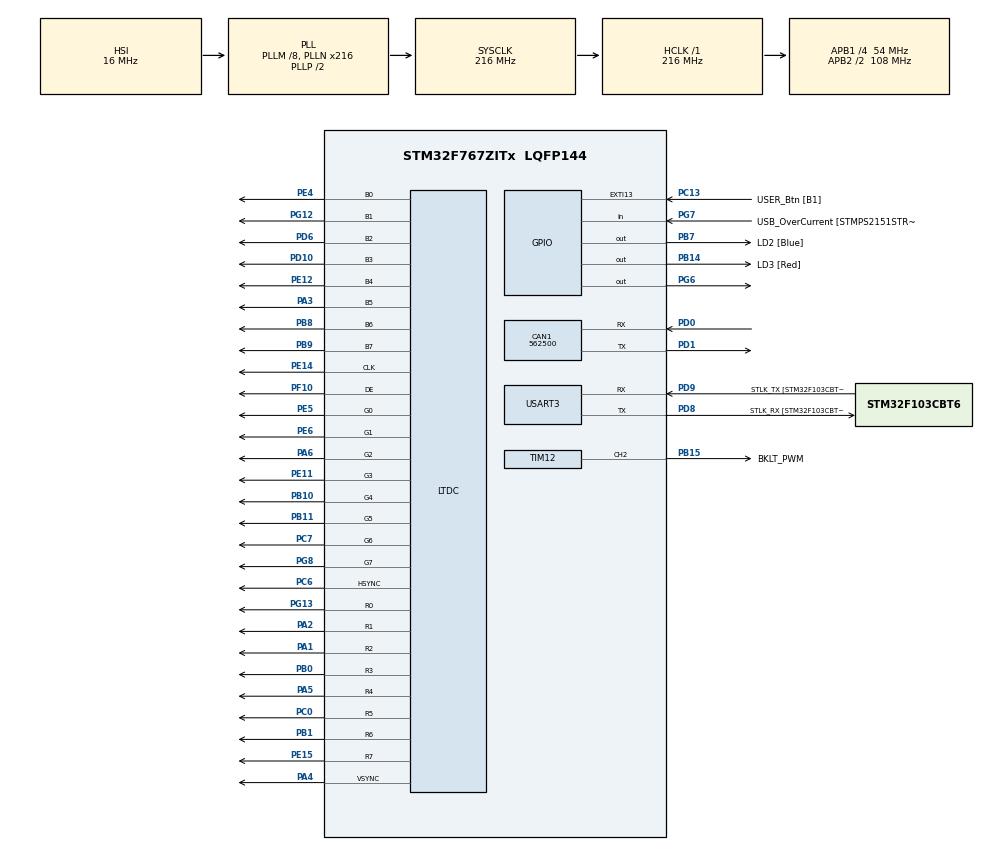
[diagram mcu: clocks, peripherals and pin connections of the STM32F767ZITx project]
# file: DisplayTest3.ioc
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ADC1.Channel-0\#ChannelRegularConversion=ADC_CHANNEL_TEMPSENSOR
ADC1.NbrOfConversionFlag=1
ADC1.Rank-0\#ChannelRegularConversion=1
ADC1.SamplingTime-0\#ChannelRegularConversion=ADC_SAMPLETIME_3CYCLES
ADC1.master=1
CAN1.BS1=CAN_BS1_2TQ
CAN1.BS2=CAN_BS2_3TQ
CAN1.CalculateBaudRate=562500
CAN1.CalculateTimeBit=1777
CAN1.CalculateTimeQuantum=296.2962962962963
CAN1.SJW=CAN_SJW_2TQ
CORTEX_M7.ART_ACCELERATOR_ENABLE=1
CORTEX_M7.CPU_DCache=Disabled
CORTEX_M7.CPU_ICache=Enabled
CORTEX_M7.PREFETCH_ENABLE=1
DMA2D.ColorMode=DMA2D_OUTPUT_RGB565
LTDC.ActiveW=480
LTDC.Alpha0_L0=128
LTDC.Alpha_L0=255
LTDC.BlendingFactor1_L0=LTDC_BLENDING_FACTOR1_PAxCA
LTDC.BlendingFactor2_L0=LTDC_BLENDING_FACTOR2_PAxCA
LTDC.Blue_L0=255
LTDC.Green=0
LTDC.Green_L0=0
LTDC.HBP=40
LTDC.HFP=5
LTDC.ImageHeight_L0=RENDER_V
LTDC.ImageWidth_L0=RENDER_H
LTDC.Layers=0
LTDC.PixelFormat_L0=LTDC_PIXEL_FORMAT_RGB565
LTDC.Red=0
LTDC.Red_L0=0
LTDC.VBP=8
LTDC.VFP=8
LTDC.WindowX1_L0=RENDER_H
LTDC.WindowY1_L0=RENDER_V
Mcu.Family=STM32F7
Mcu.Name=STM32F767ZITx
Mcu.Package=LQFP144
Mcu.UserConstants=RENDER_H,480;RENDER_V,272
NVIC.DMA2D_IRQn=true\:0\:0\:false\:false\:true\:true\:true\:true
NVIC.PriorityGroup=NVIC_PRIORITYGROUP_4
PA1.Mode=RGB888
PA1.Signal=LTDC_R2
PA10.GPIO_Label=USB_ID
PA10.Signal=USB_OTG_FS_ID
PA11.GPIO_Label=USB_DM
PA11.Signal=USB_OTG_FS_DM
PA12.GPIO_Label=USB_DP
PA12.Signal=USB_OTG_FS_DP
PA13.GPIO_Label=TMS
PA13.Mode=Serial_Wire
PA13.Signal=SYS_JTMS-SWDIO
PA14.GPIO_Label=TCK
PA14.Mode=Serial_Wire
PA14.Signal=SYS_JTCK-SWCLK
PA2.Mode=RGB888
PA2.Signal=LTDC_R1
PA3.Mode=RGB888
PA3.Signal=LTDC_B5
PA4.Mode=RGB888
PA4.Signal=LTDC_VSYNC
PA5.Mode=RGB888
PA5.Signal=LTDC_R4
PA6.Mode=RGB888
PA6.Signal=LTDC_G2
PA7.GPIO_Label=RMII_CRS_DV [LAN8742A-CZ-TR_CRS_DV]
PA7.Signal=ETH_CRS_DV
PA8.GPIO_Label=USB_SOF [TP1]
PA8.Signal=USB_OTG_FS_SOF
PA9.GPIO_Label=USB_VBUS
PA9.Signal=USB_OTG_FS_VBUS
PB0.Mode=RGB888
PB0.Signal=LTDC_R3
PB1.Mode=RGB888
PB1.Signal=LTDC_R6
PB10.Mode=RGB888
PB10.Signal=LTDC_G4
PB11.Mode=RGB888
PB11.Signal=LTDC_G5
PB14.GPIO_Label=LD3 [Red]
PB14.Signal=GPIO_Output
PB15.GPIO_Label=BKLT_PWM
PB15.Signal=S_TIM12_CH2
PB3.GPIO_Label=SWO
PB3.Signal=SYS_JTDO-SWO
PB7.GPIO_Label=LD2 [Blue]
PB7.Signal=GPIO_Output
PB8.Mode=RGB888
PB8.Signal=LTDC_B6
PB9.Mode=RGB888
PB9.Signal=LTDC_B7
PC0.Mode=RGB888
PC0.Signal=LTDC_R5
PC1.GPIO_Label=RMII_MDC [LAN8742A-CZ-TR_MDC]
PC1.Signal=ETH_MDC
PC13.GPIO_Label=USER_Btn [B1]
PC13.Signal=GPXTI13
PC14/OSC32_IN.Signal=RCC_OSC32_IN
PC15/OSC32_OUT.Signal=RCC_OSC32_OUT
PC4.GPIO_Label=RMII_RXD0 [LAN8742A-CZ-TR_RXD0]
PC4.Signal=ETH_RXD0
PC5.GPIO_Label=RMII_RXD1 [LAN8742A-CZ-TR_RXD1]
PC5.Signal=ETH_RXD1
PC6.Mode=RGB888
PC6.Signal=LTDC_HSYNC
PC7.Mode=RGB888
PC7.Signal=LTDC_G6
PD0.Mode=CAN_Activate
PD0.Signal=CAN1_RX
PD1.Mode=CAN_Activate
PD1.Signal=CAN1_TX
PD10.Mode=RGB888
PD10.Signal=LTDC_B3
PD6.Mode=RGB888
PD6.Signal=LTDC_B2
PD8.GPIO_Label=STLK_RX [STM32F103CBT6_PA3]
PD8.Mode=Asynchronous
PD8.Signal=USART3_TX
PD9.GPIO_Label=STLK_TX [STM32F103CBT6_PA2]
PD9.Mode=Asynchronous
PD9.Signal=USART3_RX
PE11.Mode=RGB888
PE11.Signal=LTDC_G3
PE12.Mode=RGB888
PE12.Signal=LTDC_B4
PE14.Mode=RGB888
PE14.Signal=LTDC_CLK
PE15.Mode=RGB888
PE15.Signal=LTDC_R7
PE4.Mode=RGB888
PE4.Signal=LTDC_B0
PE5.Mode=RGB888
PE5.Signal=LTDC_G0
PE6.Mode=RGB888
PE6.Signal=LTDC_G1
PF10.Mode=RGB888
PF10.Signal=LTDC_DE
PG12.Mode=RGB888
PG12.Signal=LTDC_B1
PG13.Mode=RGB888
PG13.Signal=LTDC_R0
PG6.Signal=GPIO_Output
PG7.GPIO_Label=USB_OverCurrent [STMPS2151STR_FAULT]
PG7.Signal=GPIO_Input
PG8.Mode=RGB888
PG8.Signal=LTDC_G7
PH0/OSC_IN.GPIO_Label=MCO [STM32F103CBT6_PA8]
PH0/OSC_IN.Signal=RCC_OSC_IN
PH1/OSC_OUT.Signal=RCC_OSC_OUT
ProjectManager.HeapSize=0x200
ProjectManager.StackSize=0x400
ProjectManager.TargetToolchain=STM32CubeIDE
RCC.48MHZClocksFreq_Value=24000000
RCC.AHBFreq_Value=216000000
RCC.APB1CLKDivider=RCC_HCLK_DIV4
RCC.APB1Freq_Value=54000000
RCC.APB1TimFreq_Value=108000000
RCC.APB2CLKDivider=RCC_HCLK_DIV2
RCC.APB2Freq_Value=108000000
RCC.APB2TimFreq_Value=216000000
RCC.CortexFreq_Value=216000000
RCC.HCLKFreq_Value=216000000
RCC.HSE_VALUE=8000000
RCC.HSI_VALUE=16000000
RCC.LSE_VALUE=32768
RCC.PLLM=8
RCC.PLLMUL=RCC_PLL_MUL9
RCC.PLLN=216
RCC.PLLQ=9
RCC.PLLSAIN=96
RCC.PLLSAIRDiv=RCC_PLLSAIDIVR_8
RCC.PRESCALERUSB=RCC_USBCLKSOURCE_PLL_DIV1_5
RCC.SYSCLKFreq_VALUE=216000000
RCC.SYSCLKSource=RCC_SYSCLKSOURCE_PLLCLK
RCC.SYSCLKSourceVirtual=RCC_SYSCLKSOURCE_PLLCLK
RCC.USBFreq_Value=48000000
RCC.VCOOutputFreq_Value=432000000
SH.S_TIM12_CH2.0=TIM12_CH2,PWM Generation2 CH2
TIM12.Channel-PWM\ Generation2\ CH2=TIM_CHANNEL_2
USART3.VirtualMode-Asynchronous=VM_ASYNC
VP_ADC1_TempSens_Input.Mode=IN-TempSens
VP_ADC1_Vref_Input.Mode=IN-Vrefint
VP_DMA2D_VS_DMA2D.Mode=DMA2D_Activate
VP_TIM12_VS_ClockSourceINT.Mode=Internal
board=NUCLEO-F767ZI

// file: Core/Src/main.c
/* USER CODE BEGIN Header */
/**
  ******************************************************************************
  * @file           : main.c
  * @brief          : Main program body
  ******************************************************************************
  * @attention
  *
  * Copyright (c) 2024 STMicroelectronics.
  * All rights reserved.
  *
  * This software is licensed under terms that can be found in the LICENSE file
  * in the root directory of this software component.
  * If no LICENSE file comes with this software, it is provided AS-IS.
  *
  ******************************************************************************
  */
/* USER CODE END Header */
#include "main.h"

/* USER CODE BEGIN Includes */

#include "lvgl.h"
//#include "demos/stress/lv_demo_stress.h"
#include "ui.h"

/* USER CODE END Includes */

ADC_HandleTypeDef hadc1;

CAN_HandleTypeDef hcan1;

DMA2D_HandleTypeDef hdma2d;

LTDC_HandleTypeDef hltdc;

TIM_HandleTypeDef htim12;

UART_HandleTypeDef huart3;

/* USER CODE BEGIN PV */

uint32_t adc_data;
int temp;

/* USER CODE END PV */

void SystemClock_Config(void);
static void MX_GPIO_Init(void);
static void MX_USART3_UART_Init(void);
static void MX_CAN1_Init(void);
static void MX_LTDC_Init(void);
static void MX_DMA2D_Init(void);
static void MX_TIM12_Init(void);
static void MX_ADC1_Init(void);

int main(void)
{

  /* Enable the CPU Cache */

  /* Enable I-Cache---------------------------------------------------------*/
  SCB_EnableICache();

  /* MCU Configuration--------------------------------------------------------*/

  /* Reset of all peripherals, Initializes the Flash interface and the Systick. */
  HAL_Init();

  /* Configure the system clock */
  SystemClock_Config();

  /* Initialize all configured peripherals */
  MX_GPIO_Init();
  MX_USART3_UART_Init();
  MX_CAN1_Init();
  MX_LTDC_Init();
  MX_DMA2D_Init();
  MX_TIM12_Init();
  MX_ADC1_Init();
  /* USER CODE BEGIN 2 */

  // prepare temp sensor - define variable to be updated in main, start and calibrate adc with vrefint
//  HAL_ADC_Start(&hadc1);
//  HAL_ADCEx_Calibration_Start(&hadc1);

  // setup lvgl
  lv_init();
  lv_port_disp_init(&hltdc);
//  lv_demo_benchmark();
  ui_init();
  // show screen 2
  _ui_screen_change(&ui_Screen_Dark, LV_SCR_LOAD_ANIM_FADE_ON, 500, 0, ui_Screen_Dark_screen_init);
  _ui_screen_change(&ui_Screen_Loading, LV_SCR_LOAD_ANIM_FADE_ON, 500, 1000, ui_Screen_Loading_screen_init);
  _ui_screen_change(&ui_Screen_Main, LV_SCR_LOAD_ANIM_FADE_ON, 100, 5000, ui_Screen_Main_screen_init);

  /* USER CODE END 2 */

  /* Infinite loop */
  while (1)
  {

    /* USER CODE BEGIN 3 */
	// get temp sensor data
//	  HAL_ADC_PollForConversion(&hadc1, 100);
//	  adc_data = HAL_ADC_GetValue(&hadc1);
//	  temp = ((adc_data - 760) * 100) / 16;

	lv_task_handler();  // to be added
	HAL_Delay(5);  // to be added
  }
  /* USER CODE END 3 */
}

void SystemClock_Config(void)
{
  RCC_OscInitTypeDef RCC_OscInitStruct = {0};
  RCC_ClkInitTypeDef RCC_ClkInitStruct = {0};

  /** Configure the main internal regulator output voltage
  */
  __HAL_RCC_PWR_CLK_ENABLE();
  __HAL_PWR_VOLTAGESCALING_CONFIG(PWR_REGULATOR_VOLTAGE_SCALE1);

  /** Initializes the RCC Oscillators according to the specified parameters
  * in the RCC_OscInitTypeDef structure.
  */
  RCC_OscInitStruct.OscillatorType = RCC_OSCILLATORTYPE_HSI;
  RCC_OscInitStruct.HSIState = RCC_HSI_ON;
  RCC_OscInitStruct.HSICalibrationValue = RCC_HSICALIBRATION_DEFAULT;
  RCC_OscInitStruct.PLL.PLLState = RCC_PLL_ON;
  RCC_OscInitStruct.PLL.PLLSource = RCC_PLLSOURCE_HSI;
  RCC_OscInitStruct.PLL.PLLM = 8;
  RCC_OscInitStruct.PLL.PLLN = 216;
  RCC_OscInitStruct.PLL.PLLP = RCC_PLLP_DIV2;
  RCC_OscInitStruct.PLL.PLLQ = 9;
  RCC_OscInitStruct.PLL.PLLR = 2;
  if (HAL_RCC_OscConfig(&RCC_OscInitStruct) != HAL_OK)
  {
    Error_Handler();
  }

  /** Activate the Over-Drive mode
  */
  if (HAL_PWREx_EnableOverDrive() != HAL_OK)
  {
    Error_Handler();
  }

  /** Initializes the CPU, AHB and APB buses clocks
  */
  RCC_ClkInitStruct.ClockType = RCC_CLOCKTYPE_HCLK|RCC_CLOCKTYPE_SYSCLK
                              |RCC_CLOCKTYPE_PCLK1|RCC_CLOCKTYPE_PCLK2;
  RCC_ClkInitStruct.SYSCLKSource = RCC_SYSCLKSOURCE_PLLCLK;
  RCC_ClkInitStruct.AHBCLKDivider = RCC_SYSCLK_DIV1;
  RCC_ClkInitStruct.APB1CLKDivider = RCC_HCLK_DIV4;
  RCC_ClkInitStruct.APB2CLKDivider = RCC_HCLK_DIV2;

  if (HAL_RCC_ClockConfig(&RCC_ClkInitStruct, FLASH_LATENCY_7) != HAL_OK)
  {
    Error_Handler();
  }
}

static void MX_ADC1_Init(void)
{

  ADC_ChannelConfTypeDef sConfig = {0};

  /** Configure the global features of the ADC (Clock, Resolution, Data Alignment and number of conversion)
  */
  hadc1.Instance = ADC1;
  hadc1.Init.ClockPrescaler = ADC_CLOCK_SYNC_PCLK_DIV4;
  hadc1.Init.Resolution = ADC_RESOLUTION_12B;
  hadc1.Init.ScanConvMode = ADC_SCAN_DISABLE;
  hadc1.Init.ContinuousConvMode = DISABLE;
  hadc1.Init.DiscontinuousConvMode = DISABLE;
  hadc1.Init.ExternalTrigConvEdge = ADC_EXTERNALTRIGCONVEDGE_NONE;
  hadc1.Init.ExternalTrigConv = ADC_SOFTWARE_START;
  hadc1.Init.DataAlign = ADC_DATAALIGN_RIGHT;
  hadc1.Init.NbrOfConversion = 1;
  hadc1.Init.DMAContinuousRequests = DISABLE;
  hadc1.Init.EOCSelection = ADC_EOC_SINGLE_CONV;
  if (HAL_ADC_Init(&hadc1) != HAL_OK)
  {
    Error_Handler();
  }

  /** Configure for the selected ADC regular channel its corresponding rank in the sequencer and its sample time.
  */
  sConfig.Channel = ADC_CHANNEL_TEMPSENSOR;
  sConfig.Rank = ADC_REGULAR_RANK_1;
  sConfig.SamplingTime = ADC_SAMPLETIME_3CYCLES;
  if (HAL_ADC_ConfigChannel(&hadc1, &sConfig) != HAL_OK)
  {
    Error_Handler();
  }

}

static void MX_CAN1_Init(void)
{

  hcan1.Instance = CAN1;
  hcan1.Init.Prescaler = 16;
  hcan1.Init.Mode = CAN_MODE_NORMAL;
  hcan1.Init.SyncJumpWidth = CAN_SJW_2TQ;
  hcan1.Init.TimeSeg1 = CAN_BS1_2TQ;
  hcan1.Init.TimeSeg2 = CAN_BS2_3TQ;
  hcan1.Init.TimeTriggeredMode = DISABLE;
  hcan1.Init.AutoBusOff = DISABLE;
  hcan1.Init.AutoWakeUp = DISABLE;
  hcan1.Init.AutoRetransmission = DISABLE;
  hcan1.Init.ReceiveFifoLocked = DISABLE;
  hcan1.Init.TransmitFifoPriority = DISABLE;
  if (HAL_CAN_Init(&hcan1) != HAL_OK)
  {
    Error_Handler();
  }

}

static void MX_DMA2D_Init(void)
{

  hdma2d.Instance = DMA2D;
  hdma2d.Init.Mode = DMA2D_M2M;
  hdma2d.Init.ColorMode = DMA2D_OUTPUT_RGB565;
  hdma2d.Init.OutputOffset = 0;
  hdma2d.LayerCfg[1].InputOffset = 0;
  hdma2d.LayerCfg[1].InputColorMode = DMA2D_INPUT_RGB565;
  hdma2d.LayerCfg[1].AlphaMode = DMA2D_NO_MODIF_ALPHA;
  hdma2d.LayerCfg[1].InputAlpha = 0;
  hdma2d.LayerCfg[1].AlphaInverted = DMA2D_REGULAR_ALPHA;
  hdma2d.LayerCfg[1].RedBlueSwap = DMA2D_RB_REGULAR;
  if (HAL_DMA2D_Init(&hdma2d) != HAL_OK)
  {
    Error_Handler();
  }
  if (HAL_DMA2D_ConfigLayer(&hdma2d, 1) != HAL_OK)
  {
    Error_Handler();
  }

}

static void MX_LTDC_Init(void)
{

  LTDC_LayerCfgTypeDef pLayerCfg = {0};

  hltdc.Instance = LTDC;
  hltdc.Init.HSPolarity = LTDC_HSPOLARITY_AL;
  hltdc.Init.VSPolarity = LTDC_VSPOLARITY_AL;
  hltdc.Init.DEPolarity = LTDC_DEPOLARITY_AL;
  hltdc.Init.PCPolarity = LTDC_PCPOLARITY_IPC;
  hltdc.Init.HorizontalSync = 7;
  hltdc.Init.VerticalSync = 3;
  hltdc.Init.AccumulatedHBP = 47;
  hltdc.Init.AccumulatedVBP = 11;
  hltdc.Init.AccumulatedActiveW = 527;
  hltdc.Init.AccumulatedActiveH = 491;
  hltdc.Init.TotalWidth = 532;
  hltdc.Init.TotalHeigh = 499;
  hltdc.Init.Backcolor.Blue = 0;
  hltdc.Init.Backcolor.Green = 0;
  hltdc.Init.Backcolor.Red = 0;
  if (HAL_LTDC_Init(&hltdc) != HAL_OK)
  {
    Error_Handler();
  }
  pLayerCfg.WindowX0 = 0;
  pLayerCfg.WindowX1 = RENDER_H;
  pLayerCfg.WindowY0 = 0;
  pLayerCfg.WindowY1 = RENDER_V;
  pLayerCfg.PixelFormat = LTDC_PIXEL_FORMAT_RGB565;
  pLayerCfg.Alpha = 255;
  pLayerCfg.Alpha0 = 128;
  pLayerCfg.BlendingFactor1 = LTDC_BLENDING_FACTOR1_PAxCA;
  pLayerCfg.BlendingFactor2 = LTDC_BLENDING_FACTOR2_PAxCA;
  pLayerCfg.FBStartAdress = 0;
  pLayerCfg.ImageWidth = RENDER_H;
  pLayerCfg.ImageHeight = RENDER_V;
  pLayerCfg.Backcolor.Blue = 255;
  pLayerCfg.Backcolor.Green = 0;
  pLayerCfg.Backcolor.Red = 0;
  if (HAL_LTDC_ConfigLayer(&hltdc, &pLayerCfg, 0) != HAL_OK)
  {
    Error_Handler();
  }

}

static void MX_TIM12_Init(void)
{

  TIM_ClockConfigTypeDef sClockSourceConfig = {0};
  TIM_OC_InitTypeDef sConfigOC = {0};

  htim12.Instance = TIM12;
  htim12.Init.Prescaler = 0;
  htim12.Init.CounterMode = TIM_COUNTERMODE_UP;
  htim12.Init.Period = 65535;
  htim12.Init.ClockDivision = TIM_CLOCKDIVISION_DIV1;
  htim12.Init.AutoReloadPreload = TIM_AUTORELOAD_PRELOAD_DISABLE;
  if (HAL_TIM_Base_Init(&htim12) != HAL_OK)
  {
    Error_Handler();
  }
  sClockSourceConfig.ClockSource = TIM_CLOCKSOURCE_INTERNAL;
  if (HAL_TIM_ConfigClockSource(&htim12, &sClockSourceConfig) != HAL_OK)
  {
    Error_Handler();
  }
  if (HAL_TIM_PWM_Init(&htim12) != HAL_OK)
  {
    Error_Handler();
  }
  sConfigOC.OCMode = TIM_OCMODE_PWM1;
  sConfigOC.Pulse = 0;
  sConfigOC.OCPolarity = TIM_OCPOLARITY_HIGH;
  sConfigOC.OCFastMode = TIM_OCFAST_DISABLE;
  if (HAL_TIM_PWM_ConfigChannel(&htim12, &sConfigOC, TIM_CHANNEL_2) != HAL_OK)
  {
    Error_Handler();
  }
  HAL_TIM_MspPostInit(&htim12);

}

static void MX_USART3_UART_Init(void)
{

  huart3.Instance = USART3;
  huart3.Init.BaudRate = 115200;
  huart3.Init.WordLength = UART_WORDLENGTH_8B;
  huart3.Init.StopBits = UART_STOPBITS_1;
  huart3.Init.Parity = UART_PARITY_NONE;
  huart3.Init.Mode = UART_MODE_TX_RX;
  huart3.Init.HwFlowCtl = UART_HWCONTROL_NONE;
  huart3.Init.OverSampling = UART_OVERSAMPLING_16;
  huart3.Init.OneBitSampling = UART_ONE_BIT_SAMPLE_DISABLE;
  huart3.AdvancedInit.AdvFeatureInit = UART_ADVFEATURE_NO_INIT;
  if (HAL_UART_Init(&huart3) != HAL_OK)
  {
    Error_Handler();
  }

}

static void MX_GPIO_Init(void)
{
  GPIO_InitTypeDef GPIO_InitStruct = {0};

  /* GPIO Ports Clock Enable */
  __HAL_RCC_GPIOE_CLK_ENABLE();
  __HAL_RCC_GPIOC_CLK_ENABLE();
  __HAL_RCC_GPIOF_CLK_ENABLE();
  __HAL_RCC_GPIOH_CLK_ENABLE();
  __HAL_RCC_GPIOA_CLK_ENABLE();
  __HAL_RCC_GPIOB_CLK_ENABLE();
  __HAL_RCC_GPIOD_CLK_ENABLE();
  __HAL_RCC_GPIOG_CLK_ENABLE();

  /*Configure GPIO pin Output Level */
  HAL_GPIO_WritePin(GPIOB, LD3_Pin|LD2_Pin, GPIO_PIN_RESET);

  /*Configure GPIO pin Output Level */
  HAL_GPIO_WritePin(GPIOG, GPIO_PIN_6, GPIO_PIN_RESET);

  /*Configure GPIO pin : USER_Btn_Pin */
  GPIO_InitStruct.Pin = USER_Btn_Pin;
  GPIO_InitStruct.Mode = GPIO_MODE_IT_RISING;
  GPIO_InitStruct.Pull = GPIO_NOPULL;
  HAL_GPIO_Init(USER_Btn_GPIO_Port, &GPIO_InitStruct);

  /*Configure GPIO pins : RMII_MDC_Pin RMII_RXD0_Pin RMII_RXD1_Pin */
  GPIO_InitStruct.Pin = RMII_MDC_Pin|RMII_RXD0_Pin|RMII_RXD1_Pin;
  GPIO_InitStruct.Mode = GPIO_MODE_AF_PP;
  GPIO_InitStruct.Pull = GPIO_NOPULL;
  GPIO_InitStruct.Speed = GPIO_SPEED_FREQ_VERY_HIGH;
  GPIO_InitStruct.Alternate = GPIO_AF11_ETH;
  HAL_GPIO_Init(GPIOC, &GPIO_InitStruct);

  /*Configure GPIO pin : RMII_CRS_DV_Pin */
  GPIO_InitStruct.Pin = RMII_CRS_DV_Pin;
  GPIO_InitStruct.Mode = GPIO_MODE_AF_PP;
  GPIO_InitStruct.Pull = GPIO_NOPULL;
  GPIO_InitStruct.Speed = GPIO_SPEED_FREQ_VERY_HIGH;
  GPIO_InitStruct.Alternate = GPIO_AF11_ETH;
  HAL_GPIO_Init(RMII_CRS_DV_GPIO_Port, &GPIO_InitStruct);

  /*Configure GPIO pins : LD3_Pin LD2_Pin */
  GPIO_InitStruct.Pin = LD3_Pin|LD2_Pin;
  GPIO_InitStruct.Mode = GPIO_MODE_OUTPUT_PP;
  GPIO_InitStruct.Pull = GPIO_NOPULL;
  GPIO_InitStruct.Speed = GPIO_SPEED_FREQ_LOW;
  HAL_GPIO_Init(GPIOB, &GPIO_InitStruct);

  /*Configure GPIO pin : PG6 */
  GPIO_InitStruct.Pin = GPIO_PIN_6;
  GPIO_InitStruct.Mode = GPIO_MODE_OUTPUT_PP;
  GPIO_InitStruct.Pull = GPIO_NOPULL;
  GPIO_InitStruct.Speed = GPIO_SPEED_FREQ_LOW;
  HAL_GPIO_Init(GPIOG, &GPIO_InitStruct);

  /*Configure GPIO pin : USB_OverCurrent_Pin */
  GPIO_InitStruct.Pin = USB_OverCurrent_Pin;
  GPIO_InitStruct.Mode = GPIO_MODE_INPUT;
  GPIO_InitStruct.Pull = GPIO_NOPULL;
  HAL_GPIO_Init(USB_OverCurrent_GPIO_Port, &GPIO_InitStruct);

  /*Configure GPIO pins : USB_SOF_Pin USB_ID_Pin USB_DM_Pin USB_DP_Pin */
  GPIO_InitStruct.Pin = USB_SOF_Pin|USB_ID_Pin|USB_DM_Pin|USB_DP_Pin;
  GPIO_InitStruct.Mode = GPIO_MODE_AF_PP;
  GPIO_InitStruct.Pull = GPIO_NOPULL;
  GPIO_InitStruct.Speed = GPIO_SPEED_FREQ_VERY_HIGH;
  GPIO_InitStruct.Alternate = GPIO_AF10_OTG_FS;
  HAL_GPIO_Init(GPIOA, &GPIO_InitStruct);

  /*Configure GPIO pin : USB_VBUS_Pin */
  GPIO_InitStruct.Pin = USB_VBUS_Pin;
  GPIO_InitStruct.Mode = GPIO_MODE_INPUT;
  GPIO_InitStruct.Pull = GPIO_NOPULL;
  HAL_GPIO_Init(USB_VBUS_GPIO_Port, &GPIO_InitStruct);

}

void Error_Handler(void)
{
  __disable_irq();
  while (1)
  {
  }
}
